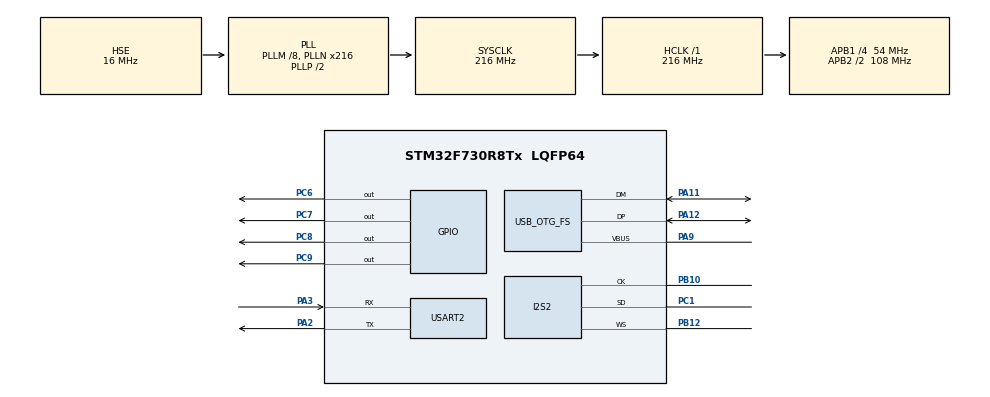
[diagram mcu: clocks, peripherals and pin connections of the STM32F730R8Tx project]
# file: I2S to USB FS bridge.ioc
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CORTEX_M7.ART_ACCLERATOR_ENABLE=0
Dma.Request0=SPI2_RX
Dma.SPI2_RX.0.Direction=DMA_PERIPH_TO_MEMORY
Dma.SPI2_RX.0.FIFOMode=DMA_FIFOMODE_DISABLE
Dma.SPI2_RX.0.Instance=DMA1_Stream3
Dma.SPI2_RX.0.MemDataAlignment=DMA_MDATAALIGN_HALFWORD
Dma.SPI2_RX.0.MemInc=DMA_MINC_ENABLE
Dma.SPI2_RX.0.Mode=DMA_CIRCULAR
Dma.SPI2_RX.0.PeriphDataAlignment=DMA_PDATAALIGN_HALFWORD
Dma.SPI2_RX.0.PeriphInc=DMA_PINC_DISABLE
Dma.SPI2_RX.0.Priority=DMA_PRIORITY_VERY_HIGH
I2S2.AudioFreq=I2S_AUDIOFREQ_96K
I2S2.AudioFreqCustom=88200
I2S2.CPOL=I2S_CPOL_HIGH
I2S2.DataFormat=I2S_DATAFORMAT_24B
I2S2.ErrorAudioFreq=-2.34 %
I2S2.FullDuplexMode=I2S_FULLDUPLEXMODE_DISABLE
I2S2.Instance=SPI$Index
I2S2.Mode=I2S_MODE_SLAVE_RX
I2S2.RealAudioFreq=93.75 KHz
I2S2.Standard=I2S_STANDARD_PHILIPS
I2S2.VirtualMode=I2S_MODE_SLAVE
Mcu.Family=STM32F7
Mcu.Name=STM32F730R8Tx
Mcu.Package=LQFP64
NVIC.DMA1_Stream3_IRQn=true\:2\:0\:true\:false\:true\:true\:true
NVIC.OTG_FS_IRQn=true\:3\:0\:true\:false\:true\:true\:true
NVIC.PriorityGroup=NVIC_PRIORITYGROUP_4
NVIC.SPI2_IRQn=true\:1\:0\:true\:false\:true\:true\:true
PA11.Mode=Device_Only
PA11.Signal=USB_OTG_FS_DM
PA12.Mode=Device_Only
PA12.Signal=USB_OTG_FS_DP
PA13.Mode=Serial_Wire
PA13.Signal=SYS_JTMS-SWDIO
PA14.Mode=Serial_Wire
PA14.Signal=SYS_JTCK-SWCLK
PA2.Mode=Asynchronous
PA2.Signal=USART2_TX
PA3.Mode=Asynchronous
PA3.Signal=USART2_RX
PA9.Mode=Activate_VBUS
PA9.Signal=USB_OTG_FS_VBUS
PB10.Mode=Half_Duplex_Slave
PB10.Signal=I2S2_CK
PB12.Mode=Half_Duplex_Slave
PB12.Signal=I2S2_WS
PC1.Mode=Half_Duplex_Slave
PC1.Signal=I2S2_SD
PC6.Signal=GPIO_Output
PC7.Signal=GPIO_Output
PC8.Signal=GPIO_Output
PC9.Signal=GPIO_Output
PH0-OSC_IN.Mode=HSE-External-Clock-Source
PH0-OSC_IN.Signal=RCC_OSC_IN
PH1-OSC_OUT.Mode=HSE-External-Clock-Source
PH1-OSC_OUT.Signal=RCC_OSC_OUT
ProjectManager.HeapSize=0x200
ProjectManager.StackSize=0x400
ProjectManager.TargetToolchain=STM32CubeIDE
RCC.AHBFreq_Value=216000000
RCC.APB1CLKDivider=RCC_HCLK_DIV4
RCC.APB1Freq_Value=54000000
RCC.APB1TimFreq_Value=108000000
RCC.APB2CLKDivider=RCC_HCLK_DIV2
RCC.APB2Freq_Value=108000000
RCC.APB2TimFreq_Value=216000000
RCC.CortexFreq_Value=216000000
RCC.HCLKFreq_Value=216000000
RCC.HSE_VALUE=16000000
RCC.HSI_VALUE=16000000
RCC.LSE_VALUE=32768
RCC.PLLI2SN=96
RCC.PLLM=8
RCC.PLLN=216
RCC.PLLQ=9
RCC.SYSCLKFreq_VALUE=216000000
RCC.SYSCLKSource=RCC_SYSCLKSOURCE_PLLCLK
RCC.USBFreq_Value=48000000
RCC.VCOOutputFreq_Value=432000000
USART2.VirtualMode-Asynchronous=VM_ASYNC
USB_OTG_FS.VirtualMode=Device_Only
USB_OTG_FS.battery_charging_enable=DISABLE
board=custom

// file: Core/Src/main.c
/* USER CODE BEGIN Header */
/**
 ******************************************************************************
 * @file           : main.c
 * @brief          : Main program body
 ******************************************************************************
 * @attention
 *
 * <h2><center>&copy; Copyright (c) 2020 STMicroelectronics.
 * All rights reserved.</center></h2>
 *
 * This software component is licensed by ST under Ultimate Liberty license
 * SLA0044, the "License"; You may not use this file except in compliance with
 * the License. You may obtain a copy of the License at:
 *                             www.st.com/SLA0044
 *
 ******************************************************************************
 */
/* USER CODE END Header */
#include "main.h"

/* USER CODE BEGIN Includes */
#include "i2s_to_usb_controller.h"
#include "usbd_core.h"
#include "usbd_desc.h"
#include "usbd_i2s_to_usb.h"

#include "debug_funcs.h"
/* USER CODE END Includes */

I2S_HandleTypeDef hi2s2;
DMA_HandleTypeDef hdma_spi2_rx;

UART_HandleTypeDef huart2;

PCD_HandleTypeDef hpcd_USB_OTG_FS;

/* USER CODE BEGIN PV */
USBD_HandleTypeDef hUsbDeviceFS;
/* USER CODE END PV */

void SystemClock_Config(void);
static void MX_GPIO_Init(void);
static void MX_DMA_Init(void);
static void MX_I2S2_Init(void);
static void MX_USART2_UART_Init(void);
static void MX_USB_OTG_FS_PCD_Init(void);

int main(void)
{

  /* MCU Configuration--------------------------------------------------------*/

  /* Reset of all peripherals, Initializes the Flash interface and the Systick. */
  HAL_Init();

  /* USER CODE BEGIN Init */
	controller_reset();
  /* USER CODE END Init */

  /* Configure the system clock */
  SystemClock_Config();

  /* Initialize all configured peripherals */
  MX_GPIO_Init();
  MX_DMA_Init();
  MX_I2S2_Init();
  MX_USART2_UART_Init();
  MX_USB_OTG_FS_PCD_Init();
  /* USER CODE BEGIN 2 */
	USBD_Init(&hUsbDeviceFS, &I2S_to_USB_Desc, 0);
	USBD_RegisterClass(&hUsbDeviceFS, &USBD_I2S_to_USB_ClassDriver);
	USBD_Start(&hUsbDeviceFS);
  /* USER CODE END 2 */

  /* Infinite loop */
	while (1)
	{

    /* USER CODE BEGIN 3 */
	controller_attempt_upload();
	}
  /* USER CODE END 3 */
}

void SystemClock_Config(void)
{
  RCC_OscInitTypeDef RCC_OscInitStruct = {0};
  RCC_ClkInitTypeDef RCC_ClkInitStruct = {0};
  RCC_PeriphCLKInitTypeDef PeriphClkInitStruct = {0};

  /** Configure the main internal regulator output voltage
  */
  __HAL_RCC_PWR_CLK_ENABLE();
  __HAL_PWR_VOLTAGESCALING_CONFIG(PWR_REGULATOR_VOLTAGE_SCALE1);
  /** Initializes the RCC Oscillators according to the specified parameters
  * in the RCC_OscInitTypeDef structure.
  */
  RCC_OscInitStruct.OscillatorType = RCC_OSCILLATORTYPE_HSE;
  RCC_OscInitStruct.HSEState = RCC_HSE_BYPASS;
  RCC_OscInitStruct.PLL.PLLState = RCC_PLL_ON;
  RCC_OscInitStruct.PLL.PLLSource = RCC_PLLSOURCE_HSE;
  RCC_OscInitStruct.PLL.PLLM = 8;
  RCC_OscInitStruct.PLL.PLLN = 216;
  RCC_OscInitStruct.PLL.PLLP = RCC_PLLP_DIV2;
  RCC_OscInitStruct.PLL.PLLQ = 9;
  if (HAL_RCC_OscConfig(&RCC_OscInitStruct) != HAL_OK)
  {
    Error_Handler();
  }
  /** Activate the Over-Drive mode
  */
  if (HAL_PWREx_EnableOverDrive() != HAL_OK)
  {
    Error_Handler();
  }
  /** Initializes the CPU, AHB and APB buses clocks
  */
  RCC_ClkInitStruct.ClockType = RCC_CLOCKTYPE_HCLK|RCC_CLOCKTYPE_SYSCLK
                              |RCC_CLOCKTYPE_PCLK1|RCC_CLOCKTYPE_PCLK2;
  RCC_ClkInitStruct.SYSCLKSource = RCC_SYSCLKSOURCE_PLLCLK;
  RCC_ClkInitStruct.AHBCLKDivider = RCC_SYSCLK_DIV1;
  RCC_ClkInitStruct.APB1CLKDivider = RCC_HCLK_DIV4;
  RCC_ClkInitStruct.APB2CLKDivider = RCC_HCLK_DIV2;

  if (HAL_RCC_ClockConfig(&RCC_ClkInitStruct, FLASH_LATENCY_7) != HAL_OK)
  {
    Error_Handler();
  }
  PeriphClkInitStruct.PeriphClockSelection = RCC_PERIPHCLK_USART2|RCC_PERIPHCLK_I2S
                              |RCC_PERIPHCLK_CLK48;
  PeriphClkInitStruct.PLLI2S.PLLI2SN = 96;
  PeriphClkInitStruct.PLLI2S.PLLI2SR = 2;
  PeriphClkInitStruct.PLLI2S.PLLI2SQ = 2;
  PeriphClkInitStruct.PLLI2SDivQ = 1;
  PeriphClkInitStruct.I2sClockSelection = RCC_I2SCLKSOURCE_PLLI2S;
  PeriphClkInitStruct.Usart2ClockSelection = RCC_USART2CLKSOURCE_PCLK1;
  PeriphClkInitStruct.Clk48ClockSelection = RCC_CLK48SOURCE_PLL;
  if (HAL_RCCEx_PeriphCLKConfig(&PeriphClkInitStruct) != HAL_OK)
  {
    Error_Handler();
  }
}

static void MX_I2S2_Init(void)
{

  /* USER CODE BEGIN I2S2_Init 1 */
	// Ensure that ASTRTEN = 0, so that data will be synced to the WS frame.
	CLEAR_BIT(hi2s2.Instance->I2SCFGR, SPI_I2SCFGR_ASTRTEN);

	// Enable error interrupts
	__HAL_I2S_ENABLE_IT(&hi2s2, I2S_IT_ERR);

  /* USER CODE END I2S2_Init 1 */
  hi2s2.Instance = SPI2;
  hi2s2.Init.Mode = I2S_MODE_SLAVE_RX;
  hi2s2.Init.Standard = I2S_STANDARD_PHILIPS;
  hi2s2.Init.DataFormat = I2S_DATAFORMAT_24B;
  hi2s2.Init.MCLKOutput = I2S_MCLKOUTPUT_DISABLE;
  hi2s2.Init.AudioFreq = I2S_AUDIOFREQ_96K;
  hi2s2.Init.CPOL = I2S_CPOL_HIGH;
  hi2s2.Init.ClockSource = I2S_CLOCK_PLL;
  if (HAL_I2S_Init(&hi2s2) != HAL_OK)
  {
    Error_Handler();
  }

}

static void MX_USART2_UART_Init(void)
{

  huart2.Instance = USART2;
  huart2.Init.BaudRate = 115200;
  huart2.Init.WordLength = UART_WORDLENGTH_8B;
  huart2.Init.StopBits = UART_STOPBITS_1;
  huart2.Init.Parity = UART_PARITY_NONE;
  huart2.Init.Mode = UART_MODE_TX_RX;
  huart2.Init.HwFlowCtl = UART_HWCONTROL_NONE;
  huart2.Init.OverSampling = UART_OVERSAMPLING_16;
  huart2.Init.OneBitSampling = UART_ONE_BIT_SAMPLE_DISABLE;
  huart2.AdvancedInit.AdvFeatureInit = UART_ADVFEATURE_NO_INIT;
  if (HAL_UART_Init(&huart2) != HAL_OK)
  {
    Error_Handler();
  }

}

static void MX_USB_OTG_FS_PCD_Init(void)
{

  hpcd_USB_OTG_FS.Instance = USB_OTG_FS;
  hpcd_USB_OTG_FS.Init.dev_endpoints = 6;
  hpcd_USB_OTG_FS.Init.dma_enable = DISABLE;
  hpcd_USB_OTG_FS.Init.phy_itface = PCD_PHY_EMBEDDED;
  hpcd_USB_OTG_FS.Init.Sof_enable = DISABLE;
  hpcd_USB_OTG_FS.Init.low_power_enable = DISABLE;
  hpcd_USB_OTG_FS.Init.lpm_enable = DISABLE;
  hpcd_USB_OTG_FS.Init.battery_charging_enable = DISABLE;
  hpcd_USB_OTG_FS.Init.vbus_sensing_enable = ENABLE;
  hpcd_USB_OTG_FS.Init.use_dedicated_ep1 = DISABLE;
  if (HAL_PCD_Init(&hpcd_USB_OTG_FS) != HAL_OK)
  {
    Error_Handler();
  }

}

static void MX_DMA_Init(void)
{

  /* DMA controller clock enable */
  __HAL_RCC_DMA1_CLK_ENABLE();

  /* DMA interrupt init */
  /* DMA1_Stream3_IRQn interrupt configuration */
  HAL_NVIC_SetPriority(DMA1_Stream3_IRQn, 2, 0);
  HAL_NVIC_EnableIRQ(DMA1_Stream3_IRQn);

}

static void MX_GPIO_Init(void)
{
  GPIO_InitTypeDef GPIO_InitStruct = {0};

  /* GPIO Ports Clock Enable */
  __HAL_RCC_GPIOH_CLK_ENABLE();
  __HAL_RCC_GPIOC_CLK_ENABLE();
  __HAL_RCC_GPIOA_CLK_ENABLE();
  __HAL_RCC_GPIOB_CLK_ENABLE();

  /*Configure GPIO pin Output Level */
  HAL_GPIO_WritePin(GPIOC, GPIO_PIN_6|GPIO_PIN_7|GPIO_PIN_8|GPIO_PIN_9, GPIO_PIN_RESET);

  /*Configure GPIO pins : PC6 PC7 PC8 PC9 */
  GPIO_InitStruct.Pin = GPIO_PIN_6|GPIO_PIN_7|GPIO_PIN_8|GPIO_PIN_9;
  GPIO_InitStruct.Mode = GPIO_MODE_OUTPUT_PP;
  GPIO_InitStruct.Pull = GPIO_NOPULL;
  GPIO_InitStruct.Speed = GPIO_SPEED_FREQ_LOW;
  HAL_GPIO_Init(GPIOC, &GPIO_InitStruct);

}

void Error_Handler(void)
{
}

/************************ (C) COPYRIGHT STMicroelectronics *****END OF FILE****/
